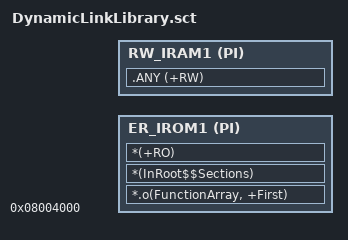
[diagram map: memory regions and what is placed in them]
#! armcc -E -I .\cfg
; *************************************************************
; *** Scatter-Loading Description File generated by uVision ***
; *************************************************************

;LR_IROM1 0x08000000 0x00080000  {    ; load region size_region
  ;ER_IROM1 0x08000000 0x00080000  {  ; load address = execution address
   ;*.o (RESET, +First)
   ;*(InRoot$$Sections)
   ;.ANY (+RO)
  ;}
  ;RW_IRAM1 0x20000000 0x00020000  {  ; RW data
   ;.ANY (+RW +ZI)
  ;}
;}


;LR_IROM1 0x08004000  0x0001000
;{
    
    ;RW_IRAM1 0x08004000 0x0000100  {  ; RW data
        ;.ANY (+RW +ZI)
    ;}
    ;ER_IROM1  +0
    ;{
        ;*.o 
        ;;*(InRoot$$Sections)
        ;* (+RO)
    ;}    
;}
;#include "../User/unit/unit_public.h"
;import unsigned int Image$$ER_IROM1$$Base;

;以下是新的，被启用的
;LR_IROM1      0x08004000 
;{    
    ;ER_IROM1  0x20000000  
    ;{
        ;*.o 
        ;;*(InRoot$$Sections)
        ;*(+RO)
    ;}
    
    ;RW_IRAM1    +0 
    ;{  ; RW data  ;0x08004000  0x0000100
        ;.ANY (+RW)
    ;}
    
    ;ZI_IRAM1    +0 
    ;{  ; RW data  ;0x08004000  0x0000100
        ;.ANY (+ZI)
    ;}
;}
;LR_IROM0    0x08004000 PI
;{
    ;ER_IROM0  0x08004000 PI
    ;{
        ;unit_public.o (FunArray, +FIRST)
        ;*(InRoot$$Sections)
        ;*(+RO)
    ;}
;}


LR_IROM1      0x08004000 PI
{    
    ER_IROM1  0x08004000 PI
    {
        *.o(FunctionArray, +First);unit_public.o (FunArray, +FIRST) 
        *(InRoot$$Sections)
        *(+RO)
    }
    
    RW_IRAM1    +0 PI
    {  ; RW data  ;0x08004000  0x0000100
        ;*.o (FunArray, +Last)
        .ANY (+RW)
    }
    
    ;ZI_IRAM1    +0 PI
    ;{  ; RW data  ;0x08004000  0x0000100
        ;.ANY (+ZI)
    ;}
}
